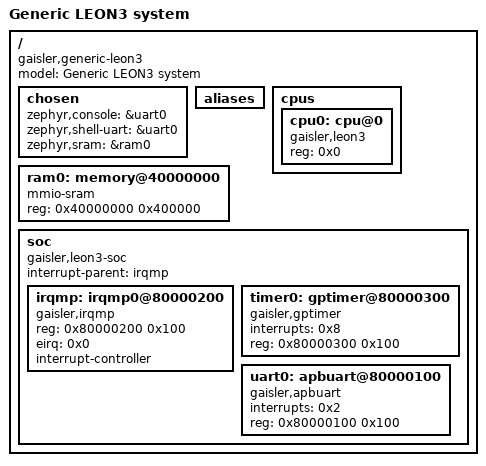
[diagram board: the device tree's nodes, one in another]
/dts-v1/;

/* node '/' defined in zephyr/dts/common/skeleton.dtsi:9 */
/ {
	#address-cells = < 0x1 >;             /* in zephyr/dts/common/skeleton.dtsi:10 */
	#size-cells = < 0x1 >;                /* in zephyr/dts/common/skeleton.dtsi:11 */
	model = "Generic LEON3 system";       /* in zephyr/boards/gaisler/generic_leon3/generic_leon3.dts:12 */
	compatible = "gaisler,generic-leon3"; /* in zephyr/boards/gaisler/generic_leon3/generic_leon3.dts:13 */

	/* node '/chosen' defined in zephyr/dts/common/skeleton.dtsi:13 */
	chosen {
		zephyr,console = &uart0;    /* in zephyr/boards/gaisler/generic_leon3/generic_leon3.dts:16 */
		zephyr,shell-uart = &uart0; /* in zephyr/boards/gaisler/generic_leon3/generic_leon3.dts:17 */
		zephyr,sram = &ram0;        /* in zephyr/boards/gaisler/generic_leon3/generic_leon3.dts:18 */
	};

	/* node '/aliases' defined in zephyr/dts/common/skeleton.dtsi:15 */
	aliases {
	};

	/* node '/cpus' defined in zephyr/dts/sparc/gaisler/leon3soc.dtsi:10 */
	cpus {
		#address-cells = < 0x1 >; /* in zephyr/dts/sparc/gaisler/leon3soc.dtsi:11 */
		#size-cells = < 0x0 >;    /* in zephyr/dts/sparc/gaisler/leon3soc.dtsi:12 */

		/* node '/cpus/cpu@0' defined in zephyr/dts/sparc/gaisler/leon3soc.dtsi:14 */
		cpu0: cpu@0 {
			compatible = "gaisler,leon3"; /* in zephyr/dts/sparc/gaisler/leon3soc.dtsi:15 */
			reg = < 0x0 >;                /* in zephyr/dts/sparc/gaisler/leon3soc.dtsi:16 */
		};
	};

	/* node '/memory@40000000' defined in zephyr/dts/sparc/gaisler/leon3soc.dtsi:20 */
	ram0: memory@40000000 {
		compatible = "mmio-sram";      /* in zephyr/dts/sparc/gaisler/leon3soc.dtsi:21 */
		reg = < 0x40000000 0x400000 >; /* in zephyr/boards/gaisler/generic_leon3/generic_leon3.dts:23 */
	};

	/* node '/soc' defined in zephyr/dts/sparc/gaisler/leon3soc.dtsi:25 */
	soc {
		#address-cells = < 0x1 >;         /* in zephyr/dts/sparc/gaisler/leon3soc.dtsi:26 */
		#size-cells = < 0x1 >;            /* in zephyr/dts/sparc/gaisler/leon3soc.dtsi:27 */
		compatible = "gaisler,leon3-soc",
		             "simple-bus";        /* in zephyr/dts/sparc/gaisler/leon3soc.dtsi:28 */
		ranges;                           /* in zephyr/dts/sparc/gaisler/leon3soc.dtsi:29 */
		interrupt-parent = < &irqmp >;    /* in zephyr/dts/sparc/gaisler/leon3soc.dtsi:30 */

		/* node '/soc/irqmp0@80000200' defined in zephyr/dts/sparc/gaisler/leon3soc.dtsi:32 */
		irqmp: irqmp0@80000200 {
			compatible = "gaisler,irqmp"; /* in zephyr/dts/sparc/gaisler/leon3soc.dtsi:33 */
			reg = < 0x80000200 0x100 >;   /* in zephyr/dts/sparc/gaisler/leon3soc.dtsi:34 */
			eirq = < 0x0 >;               /* in zephyr/dts/sparc/gaisler/leon3soc.dtsi:35 */
			interrupt-controller;         /* in zephyr/dts/sparc/gaisler/leon3soc.dtsi:36 */
			#interrupt-cells = < 0x1 >;   /* in zephyr/dts/sparc/gaisler/leon3soc.dtsi:37 */
			phandle = < 0x1 >;            /* in zephyr/dts/sparc/gaisler/leon3soc.dtsi:30 */
		};

		/* node '/soc/gptimer@80000300' defined in zephyr/dts/sparc/gaisler/leon3soc.dtsi:40 */
		timer0: gptimer@80000300 {
			compatible = "gaisler,gptimer"; /* in zephyr/dts/sparc/gaisler/leon3soc.dtsi:41 */
			interrupts = < 0x8 >;           /* in zephyr/dts/sparc/gaisler/leon3soc.dtsi:42 */
			reg = < 0x80000300 0x100 >;     /* in zephyr/dts/sparc/gaisler/leon3soc.dtsi:43 */
		};

		/* node '/soc/apbuart@80000100' defined in zephyr/dts/sparc/gaisler/leon3soc.dtsi:46 */
		uart0: apbuart@80000100 {
			compatible = "gaisler,apbuart"; /* in zephyr/dts/sparc/gaisler/leon3soc.dtsi:47 */
			interrupts = < 0x2 >;           /* in zephyr/dts/sparc/gaisler/leon3soc.dtsi:48 */
			reg = < 0x80000100 0x100 >;     /* in zephyr/dts/sparc/gaisler/leon3soc.dtsi:49 */
			status = "okay";                /* in zephyr/boards/gaisler/generic_leon3/generic_leon3.dts:27 */
		};
	};
};
